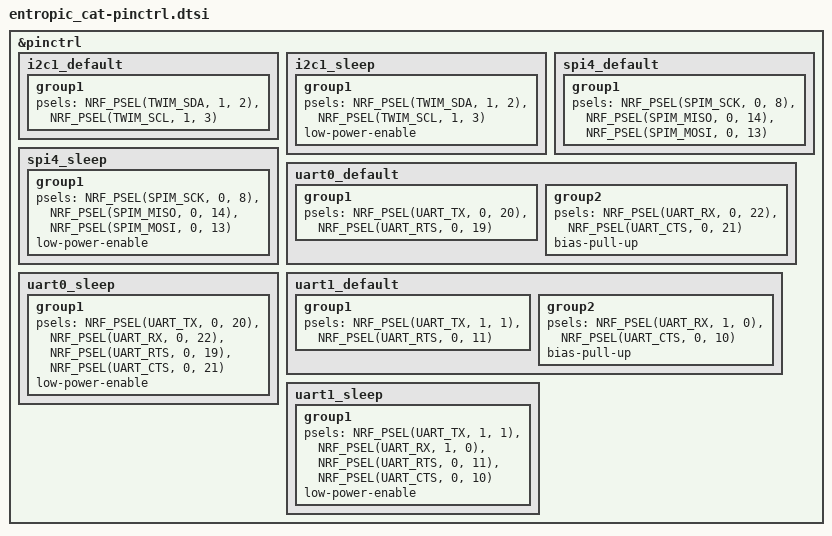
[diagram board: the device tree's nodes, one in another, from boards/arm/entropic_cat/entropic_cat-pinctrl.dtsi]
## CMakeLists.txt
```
cmake_minimum_required(VERSION 3.20.0)
find_package(Zephyr REQUIRED HINTS $ENV{ZEPHYR_BASE})

project(cat)

add_subdirectory(vendor)

target_sources(app PRIVATE src/main.c
    src/sen5x.c
    src/sunrise.c
    src/lps22hh.c)
```

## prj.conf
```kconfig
CONFIG_I2C=y

CONFIG_LOG=y
CONFIG_LOG_INFO_COLOR_GREEN=y
CONFIG_LOG_BACKEND_SHOW_COLOR=y

# Enable floats in printf calls
CONFIG_CBPRINTF_FP_SUPPORT=y

# Disable TF-M Secure UART, its addr space overlaps
# peripherals we use which causes a Bus Fault if enabled.
# See: https://academy.nordicsemi.com/courses/nrf-connect-sdk-intermediate/lessons/lesson-5-serial-peripheral-interface-spi/topic/exercise-1-10/
CONFIG_TFM_SECURE_UART=n
CONFIG_TFM_LOG_LEVEL_SILENCE=y
```

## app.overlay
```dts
&arduino_i2c {
	status = "okay";
	clock-frequency = <I2C_BITRATE_STANDARD>;
};
```

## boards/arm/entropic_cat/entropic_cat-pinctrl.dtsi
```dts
&pinctrl {
	i2c1_default: i2c1_default {
		group1 {
			psels = <NRF_PSEL(TWIM_SDA, 1, 2)>,
				<NRF_PSEL(TWIM_SCL, 1, 3)>;
		};
	};

	i2c1_sleep: i2c1_sleep {
		group1 {
			psels = <NRF_PSEL(TWIM_SDA, 1, 2)>,
				<NRF_PSEL(TWIM_SCL, 1, 3)>;
			low-power-enable;
		};
	};

	spi4_default: spi4_default {
		group1 {
			psels = <NRF_PSEL(SPIM_SCK, 0, 8)>,
				<NRF_PSEL(SPIM_MISO, 0, 14)>,
				<NRF_PSEL(SPIM_MOSI, 0, 13)>;
		};
	};

	spi4_sleep: spi4_sleep {
		group1 {
			psels = <NRF_PSEL(SPIM_SCK, 0, 8)>,
				<NRF_PSEL(SPIM_MISO, 0, 14)>,
				<NRF_PSEL(SPIM_MOSI, 0, 13)>;
			low-power-enable;
		};
	};

    /* The following are defaults from nrf5340-dk, TO BE UPDATED! */

	uart0_default: uart0_default {
		group1 {
			psels = <NRF_PSEL(UART_TX, 0, 20)>,
				<NRF_PSEL(UART_RTS, 0, 19)>;
		};
		group2 {
			psels = <NRF_PSEL(UART_RX, 0, 22)>,
				<NRF_PSEL(UART_CTS, 0, 21)>;
			bias-pull-up;
		};
	};

	uart0_sleep: uart0_sleep {
		group1 {
			psels = <NRF_PSEL(UART_TX, 0, 20)>,
				<NRF_PSEL(UART_RX, 0, 22)>,
				<NRF_PSEL(UART_RTS, 0, 19)>,
				<NRF_PSEL(UART_CTS, 0, 21)>;
			low-power-enable;
		};
	};

	uart1_default: uart1_default {
		group1 {
			psels = <NRF_PSEL(UART_TX, 1, 1)>,
				<NRF_PSEL(UART_RTS, 0, 11)>;
		};
		group2 {
			psels = <NRF_PSEL(UART_RX, 1, 0)>,
				<NRF_PSEL(UART_CTS, 0, 10)>;
			bias-pull-up;
		};
	};

	uart1_sleep: uart1_sleep {
		group1 {
			psels = <NRF_PSEL(UART_TX, 1, 1)>,
				<NRF_PSEL(UART_RX, 1, 0)>,
				<NRF_PSEL(UART_RTS, 0, 11)>,
				<NRF_PSEL(UART_CTS, 0, 10)>;
			low-power-enable;
		};
	};
};
```

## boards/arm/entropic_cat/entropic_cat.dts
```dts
// Copyright (c) 2024 Nordic Semiconductor ASA
// SPDX-License-Identifier: Apache-2.0

/dts-v1/;
#include <nordic/nrf5340_cpuappns_qkaa.dtsi>

/ {
	model = "entropic_cat";
	compatible = "entropic-engineering,entropic-cat";

	chosen {
		zephyr,sram = &sram0;
		zephyr,flash = &flash0;
		zephyr,code-partition = &slot0_ns_partition;
	};

	rgb_leds: ws2812 {
		compatible = "worldsemi,ws2812-gpio";
		chain-length = <8>;
		color-mapping = <LED_COLOR_ID_GREEN
		                 LED_COLOR_ID_RED
						 LED_COLOR_ID_BLUE>;
		gpios = <&gpio1 1 0>;
	};
};

&flash0 {
	partitions {
		compatible = "fixed-partitions";
		#address-cells = <1>;
		#size-cells = <1>;

		boot_partition: partition@0 {
			label = "mcuboot";
			reg = <0x0 0x10000>;
		};
		slot0_partition: partition@10000 {
			label = "image-0";
			reg = <0x10000 0x40000>;
		};
		slot0_ns_partition: partition@50000 {
			label = "image-0-nonsecure";
			reg = <0x50000 0x30000>;
		};
		slot1_partition: partition@80000 {
			label = "image-1";
			reg = <0x80000 0x40000>;
		};
		slot1_ns_partition: partition@c0000 {
			label = "image-1-nonsecure";
			reg = <0xc0000 0x30000>;
		};
		scratch_partition: partition@f0000 {
			label = "image-scratch";
			reg = <0xf0000 0xa000>;
		};
		storage_partition: partition@fa000 {
			label = "storage";
			reg = <0xfa000 0x6000>;
		};
	};
};



/* Default shared SRAM planning when building for nRF5340.
* This file is included by both nRF5340 CPUAPP (Application MCU)
* and nRF5340 CPUNET (Network MCU).
* - 64 kB SRAM allocated as Shared memory (sram0_shared)
* - Region defined after the image SRAM of Application MCU
*/

/ {
    chosen {
        /* shared memory reserved for the inter-processor communication */
        zephyr,ipc_shm = &sram0_shared;
    };

    reserved-memory {
        #address-cells = <1>;
        #size-cells = <1>;
        ranges;

        sram0_shared: memory@20070000 {
            /* SRAM allocated to shared memory */
            reg = <0x20070000 0x10000>;
        };
    };
};
```

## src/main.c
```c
#include <zephyr/kernel.h>
#include <zephyr/drivers/i2c.h>

#include "sensor.h"

static const struct device* dev_i2c = DEVICE_DT_GET(DT_NODELABEL(arduino_i2c));

static const struct sensor_t* sensors[] = {
    &sensor_sen5x,
    &sensor_sunrise,
    &sensor_lps22hh,
};


void sensor_read_loop(void) {
    bool is_ready = false;
    printf("Reading sensors in a loop...\n");
    while (true) {
        ARRAY_FOR_EACH(sensors, i) {
            const struct sensor_t* const s = sensors[i];
            if (s->is_faulted()) {
                printf("[sensor:%s] Faulted, re-initializing all sensors\n", s->name);
                return;
            } else if (s->is_ready(&is_ready) != 0) {
                printf("[sensor:%s] Ready check failed\n", s->name);
            } else if (!is_ready) {
                /* not ready, take no action */
            } else if (s->read() != 0) {
                printf("[sensor:%s] Read failed\n", s->name);
            } else {
                printf("[sensor:%s] success!\n", s->name);
            }
        }
        k_msleep(5000);
    }
    printf("Sensor read loop exited.\n");
}


int main(void)
{
    printf("henlo, friendo!\n");

    while (!device_is_ready(dev_i2c)) {
        printf("waiting for i2c to be ready...\n");
        k_msleep(100);
    }

    printf("i2c bus scan:\n");
    printf("    0  1  2  3  4  5  6  7  8  9  a  b  c  d  e  f\n");
    for (uint8_t y = 0; y <= 7; y++) {
        printf("%02x", y<<4);
        for (uint8_t x = 0; x <= 0xf; x++) {
            uint8_t addr = (y<<4) | x;
            uint8_t buf = 0;
            if (addr < 0x08 || addr > 0x77) {
                printf("   ");
            } else if (i2c_read(dev_i2c, &buf, 0, addr) == 0) {
                printf(" %02x", addr);
            } else {
                printf(" --");
            }
        }
        printf("\n");
    }

    while (true) {
        printf("Initializing sensors...\n");
        ARRAY_FOR_EACH(sensors, i) {
            const struct sensor_t* const s = sensors[i];
            if (s->init() != 0) {
                printf("[sensor:%s] Init failed :<\n", s->name);
            }
        }
        sensor_read_loop();
    }

    return 0;
}

//eof
```

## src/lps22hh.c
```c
#include <zephyr/drivers/i2c.h>
#include <zephyr/logging/log.h>

#include "lps22hh.h"

#include "sensor.h"

LOG_MODULE_REGISTER(lps22hh);

static const struct device* dev_i2c = DEVICE_DT_GET(DT_NODELABEL(arduino_i2c));

static int32_t io_init() { return 0; }
static int32_t io_deinit() { return 0; }
static int32_t io_get_tick() {
    LOG_ERR("%s not implemented", __PRETTY_FUNCTION__);
    k_panic();
    return 0;
}
static void io_delay(uint32_t) {
    LOG_ERR("%s not implemented", __PRETTY_FUNCTION__);
    k_panic();
}
static int32_t io_write_reg(uint16_t addr, uint16_t reg, uint8_t* data, uint16_t data_len) {
    return i2c_burst_write(dev_i2c, addr, (uint8_t)reg, data, data_len);
}
static int32_t io_read_reg(uint16_t addr, uint16_t reg, uint8_t* buf, uint16_t buf_len) {
    return i2c_burst_read(dev_i2c, addr, (uint8_t)reg, buf, buf_len);
}

static LPS22HH_Object_t obj = {0,};
static LPS22HH_IO_t io = {
    .Init = io_init,
    .DeInit = io_deinit,
    .BusType = LPS22HH_I2C_BUS,
    .Address = 0x5d,
    .WriteReg = io_write_reg,
    .ReadReg = io_read_reg,
    .GetTick = io_get_tick,
    .Delay = io_delay,
};

struct lps22hh_state_t {
    bool is_faulted;
};
static struct lps22hh_state_t state = {0,};

#define CHK(_ACT) do { \
    const int result = _ACT; \
    if (result != 0) { \
        LOG_ERR("Action %s failed with %d (%s)\n", #_ACT, result, strerror(result)); \
        state.is_faulted = true; \
        return result; \
    } \
} while(0)

int lps22hh_init()
{
    CHK(LPS22HH_RegisterBusIO(&obj, &io));
    CHK(LPS22HH_Init(&obj));
    CHK(LPS22HH_TEMP_Enable(&obj));
    CHK(LPS22HH_PRESS_Enable(&obj));
    state.is_faulted = false;
    return 0;
}

int lps22hh_is_ready(bool* is_ready)
{
    lps22hh_status_t status;
    CHK(lps22hh_status_reg_get(&(obj.Ctx), &status));
    *is_ready = status.t_da || status.p_da;
    return 0;
}

int lps22hh_read()
{
    float temp, pressure;
    CHK(LPS22HH_TEMP_GetTemperature(&obj, &temp));
    CHK(LPS22HH_PRESS_GetPressure(&obj, &pressure));
    LOG_INF("temp=%.2f  pressure=%.2f", temp, pressure);
    sunrise_update_pressure(pressure);
    return 0;
}

bool lps22hh_is_faulted()
{
    return state.is_faulted;
}

SENSOR_DEFINE(lps22hh);

//eof
```

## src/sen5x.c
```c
#include <zephyr/drivers/i2c.h>
#include <zephyr/logging/log.h>

#include "sensirion_i2c_hal.h"
#include "sen5x_i2c.h"

#include "sensor.h"

LOG_MODULE_REGISTER(sen5x);

static const struct device* dev_i2c = DEVICE_DT_GET(DT_NODELABEL(arduino_i2c));

struct sen5x_state_t {
    char name[32];
    char serial[32];
    uint8_t fw_maj, fw_min, hw_maj, hw_min, proto_maj, proto_min;
    bool fw_debug;

    double mc_pm1p0, mc_pm2p5, mc_pm4p0, mc_pm10p0;
    double humidity, temp_c;
    double voc_index, nox_index;
    uint32_t status;
    bool is_faulted;
};

static struct sen5x_state_t state = {0,};

#define CHK(_ACT) do { \
    const int result = _ACT; \
    if (result != 0) { \
        LOG_ERR("Action %s failed with %d (%s)\n", #_ACT, result, strerror(result)); \
        state.is_faulted = true; \
        return result; \
    } \
} while(0)

int sen5x_init()
{
    sensirion_i2c_hal_init(dev_i2c);
    CHK(sen5x_device_reset());
    CHK(sen5x_get_product_name(state.name, sizeof(state.name)));
    LOG_INF("name=%s", state.name);
    CHK(sen5x_get_serial_number(state.serial, sizeof(state.serial)));
    LOG_INF("serial=%s", state.serial);
    CHK(sen5x_get_version(
        &state.fw_maj, &state.fw_min, &state.fw_debug,
        &state.hw_maj, &state.hw_min,
        &state.proto_maj, &state.proto_min));
    LOG_INF("Firmware v%d.%d (debug=%s)", state.fw_maj, state.fw_min, (state.fw_debug ? "y":"n"));
    LOG_INF("Hardware v%d.%d", state.hw_maj, state.hw_min);
    LOG_INF("Protocol v%d.%d", state.proto_maj, state.proto_min);
    CHK(sen5x_start_measurement());
    return 0;
}

int sen5x_is_ready(bool* is_ready)
{
    CHK(sen5x_read_data_ready(is_ready));
    return 0;
}

int sen5x_read()
{
    uint32_t status;
    uint16_t mc_pm1p0, mc_pm2p5, mc_pm4p0, mc_pm10p0;
    int16_t humidity, temp;
    int16_t voc_index, nox_index;

    CHK(sen5x_read_and_clear_device_status(&status));
    //TODO: parse the status!!
    LOG_INF("status=%08x", status);

    CHK(sen5x_read_measured_values(
        &mc_pm1p0, &mc_pm2p5, &mc_pm4p0, &mc_pm10p0,
        &humidity, &temp, &voc_index, &nox_index));
    if (mc_pm1p0  == 0xFFFF ||
        mc_pm2p5  == 0xFFFF ||
        mc_pm4p0  == 0xFFFF ||
        mc_pm10p0 == 0xFFFF ||
        humidity  == 0x7FFF ||
        temp      == 0x7FFF ||
        voc_index == 0x7FFF ||
        nox_index == 0x7FFF)
    {
        LOG_WRN("not ready yet");
        return -EBUSY;
    }

    state.status = status;
    state.mc_pm1p0 = mc_pm1p0 / 10.0;
    state.mc_pm2p5 = mc_pm2p5 / 10.0;
    state.mc_pm4p0 = mc_pm4p0 / 10.0;
    state.mc_pm10p0 = mc_pm10p0 / 10.0;
    state.humidity = humidity / 100.0;
    state.temp_c = temp / 200.0;
    state.voc_index = voc_index / 10.0;
    state.nox_index = nox_index / 10.0;

    LOG_INF("PM(ug/m3): 1.0=%.1f  2.5=%.1f  4.0=%.1f  10.0=%.1f",
        state.mc_pm1p0, state.mc_pm2p5, state.mc_pm4p0, state.mc_pm10p0);
    LOG_INF("humidity=%.2f %%RH", state.humidity);
    LOG_INF("temp=%.3f C", state.temp_c);
    LOG_INF("voc_index=%.1f", state.voc_index);
    LOG_INF("nox_index=%.1f", state.nox_index);

    return 0;
}

bool sen5x_is_faulted()
{
    return state.is_faulted;
}

SENSOR_DEFINE(sen5x);

//eof
```

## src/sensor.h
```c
#pragma once

#include <zephyr/kernel.h>

/* Sensor definition.
 * 
 * For simplicity, state is private to each driver and 
 * only one copy is kept. If we ever need to support more
 * than one instance of a given sensor, can extend this
 * to have a state pointer and some macros to simplify
 * statically creating instances or whatever.
 */
struct sensor_t {
    char const* const name;
    int (*init)();
    int (*is_ready)(bool*);
    int (*read)();
    bool (*is_faulted)();
};

#define SENSOR_DECL(NAME) \
    extern struct sensor_t sensor_##NAME

#define SENSOR_DEFINE(NAME) \
    struct sensor_t sensor_##NAME = { \
        .name = #NAME, \
        .init = NAME##_init, \
        .is_ready = NAME##_is_ready, \
        .read = NAME##_read, \
        .is_faulted = NAME##_is_faulted, \
    }

SENSOR_DECL(sen5x);
SENSOR_DECL(sunrise);
SENSOR_DECL(lps22hh);

/* Update pressure value (hPa) for the sunrise co2 sensor */
int sunrise_update_pressure(float pressure_hpa);

//eof
```

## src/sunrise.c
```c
#include <zephyr/drivers/i2c.h>
#include <zephyr/logging/log.h>
#include <zephyr/kernel.h>

#include "sensor.h"
#include <zephyr/sys/byteorder.h>

LOG_MODULE_REGISTER(sunrise);

/* Sensor goes to sleep after this many milliseconds of SDA inactivity.
 * After this, needs another wake-up.
 * Note the sensor also goes to sleep immediately after a completed read or write sequence. */
#define TIMEOUT_MS 15
/* EEPROM writes take 25ms */
#define EEPROM_UPDATE_DELAY_MS 25

//TODO: Should we wrap all i2c calls to track last activity
// time so we can run wakeup automatically in case another
// thread interrupts us for longer than 15ms mid operation?

static const struct device* dev_i2c = DEVICE_DT_GET(DT_NODELABEL(arduino_i2c));

/* Maximum number of retries for wake-up attempts */
static const size_t MAX_RETRIES = 5;
/* Senseair Sunrise I2C device address */
static const uint16_t ADDR = 0x68;

struct sunrise_state_t {
    uint8_t count;
    //todo: timestamp for device needing wake-up?
    //todo: timestamp for device reading ready?
    int16_t pressure_0p1_hpa;
    bool is_faulted;
};
static struct sunrise_state_t state = {0,};


#pragma pack(push, 1)
#if !CONFIG_LITTLE_ENDIAN
#error "These structures assume little endian for bit packing"
#endif

/* ErrorStatus register (00h-01h) */
struct error_status_t {
    //TODO: verify this bit and byte ordering is correct
    uint8_t fatal_error                    : 1;
    uint8_t i2c_error                      : 1;
    uint8_t algorithm_error                : 1;
    uint8_t calibration_error              : 1;
    uint8_t self_diag_error                : 1;
    uint8_t out_of_range                   : 1;
    uint8_t memory_error                   : 1;
    uint8_t no_measurement_completed       : 1;

    uint8_t low_internal_regulator_voltage : 1;
    uint8_t measurement_timeout            : 1;
    uint8_t abnormal_signal_level          : 1;
    uint8_t reserved                       : 4;
    uint8_t scale_factor_error             : 1;
};
NRF_STATIC_ASSERT(sizeof(struct error_status_t) == 2, "error_status_t size wrong");

struct fw_rev_t {
    uint8_t main;
    uint8_t sub;
};
NRF_STATIC_ASSERT(sizeof(struct fw_rev_t) == 2, "fw_rev_t size wrong");

struct product_code_t {
    /* Product code (null-terminated ASCII string) */
    char code[16];
};
NRF_STATIC_ASSERT(sizeof(struct product_code_t) == 16, "product_code_t size wrong");

struct calibration_status_t {
    uint8_t _reserved_0 : 1;
    uint8_t _reserved_1 : 1;
    uint8_t factory_calibration_restored : 1;
    uint8_t abc_calibration : 1;
    uint8_t target_calibration : 1;
    uint8_t background_calibration : 1;
    uint8_t zero_calibration : 1;
    uint8_t _reserved_7 : 1;
};
NRF_STATIC_ASSERT(sizeof(struct calibration_status_t) == 1, "calibration_status_t size wrong");

/* If ABC is enabled in single measurement mode and the sensor
 * is powered down between measurements, these registers must
 * be read from the sensor after each measurement and written
 * back to the sensor after each power on (enable) before a new
 * measurement is triggered. */
struct abc_parameters_t {
    /* Time passed since last ABC calibration (hours) */
    uint16_t time;
    /* Parameters */
    uint8_t par[4];
};
NRF_STATIC_ASSERT(sizeof(struct abc_parameters_t) == 6, "abc_parameters_t size wrong");

/* If IIR filter is enabled in single measurement mode and sensor
 * is powered down between measurements, these registers must
 * be read from the sensor after each measurement and written
 * back to the sensor after each power on (enable) before a new
 * measurement is triggered. */
struct filter_parameters_t {
    /* Parameters */
    uint16_t par[7];
};
NRF_STATIC_ASSERT(sizeof(struct filter_parameters_t) == 14, "filter_parameters_t size wrong");

struct meter_control_t {
    uint8_t nrdy_disable : 1;
    uint8_t abc_disabled  : 1;
    uint8_t static_iir_filter_dis : 1;
    uint8_t dynamic_iir_filter_dis : 1;
    uint8_t pressure_compensation_dis : 1;
    uint8_t nrdy_invert_disabled : 1;
    uint8_t reserved_6 : 1;
    uint8_t reserved_7 : 1;
};
NRF_STATIC_ASSERT(sizeof(struct meter_control_t) == 1, "meter_control_t size wrong");

#pragma pack(pop)


enum calibration_cmd_t {
    CAL_RestoreFactoryCalibration = 0x7c02,
    CAL_ForcedAbcCalibration = 0x7c03,
    CAL_TargetCalibration = 0x7c05,
    CAL_BackgroundCalibration = 0x7c06,
    CAL_ZeroCalibration = 0x7c07,
};

enum measurement_mode_t {
    MODE_Continuous = 0,
    MODE_Single = 1,
};

enum scr_t {
    RESTART_SENSOR = 0xFF,
};


static inline void msleep_for_sure(int32_t ms) {
    while (ms > 0) {
        ms = k_msleep(ms);
    }
}


#define REG_RO(REGADDR,NAME,CTYPE,XFRM) \
    static inline int Read_##NAME(CTYPE* out) { \
        int result = i2c_burst_read(dev_i2c, ADDR, REGADDR, (uint8_t*)out, sizeof(CTYPE)); \
        *out = XFRM(*out); \
        return result; \
    }
#define REG_RW(REGADDR,NAME,CTYPE,XFRM) \
    REG_RO(REGADDR,NAME,CTYPE,XFRM) \
    static inline int Write_##NAME(CTYPE value) { \
        value = XFRM(value); \
        int result = i2c_burst_write(dev_i2c, ADDR, REGADDR, (uint8_t*)&value, sizeof(value)); \
        return result; \
    }
#define REG_EE(REGADDR,NAME,CTYPE,XFRM) \
    REG_RO(REGADDR,NAME,CTYPE,XFRM) \
    static inline int Write_##NAME(CTYPE value) { \
        value = XFRM(value); \
        int result = i2c_burst_write(dev_i2c, ADDR, REGADDR, (uint8_t*)&value, sizeof(value)); \
        if (result == 0) { \
            msleep_for_sure(EEPROM_UPDATE_DELAY_MS); \
        } \
        return result; \
    }

REG_RO(0x00, ErrorStatus, struct error_status_t,)
/* Measured concentration (ppm). Filtered. Pressure compensated. */
REG_RO(0x06, MeasuredConcentration_Filtered_PressureCompensated, int16_t, sys_be16_to_cpu)
/* Device temperature (°C * 100)
 * Example: 2223 means 22.23°C */
REG_RO(0x08, Temperature, int16_t, sys_be16_to_cpu)
/* Counter incremented after each measurement, 0-255. Wraps. */
REG_RO(0x0d, MeasurementCount, uint8_t,)
/* Time in present measurement cycle, in 2 second increments.
 * 0 when new measurement cycle started.
 * Example: value of 3 means 6 seconds passed in current measurement cycle */
REG_RO(0x0e, MeasurementCycleTime, uint16_t, sys_be16_to_cpu)
/* Measured concentration (ppm). Unfiltered. Pressure compensated. */
REG_RO(0x10, MeasuredConcentration_Unfiltered_PressureCompensated, int16_t, sys_be16_to_cpu)
/* Measured concentration (ppm). Filtered. Not pressure compensated. */
REG_RO(0x12, MeasuredConcentration_Filtered, int16_t, sys_be16_to_cpu)
/* Measured concentration (ppm). Unfiltered. Not pressure compensated. */
REG_RO(0x14, MeasuredConcentration_Unfiltered, int16_t, sys_be16_to_cpu)
/* Measured concentration, scaled by (TODO) */
REG_RO(0x1a, ScaledMeasuredConcentration, int16_t, sys_be16_to_cpu)
/* Counts while sensor is powered up. Unit: hours */
REG_RO(0x2a, ElapsedTimeCounter, uint32_t, sys_be32_to_cpu)
REG_RO(0x2f, FirmwareType, uint8_t,)
REG_RO(0x38, FirmwareRevision, struct fw_rev_t,)
REG_RO(0x3a, SensorID, uint32_t, sys_be32_to_cpu)
REG_RO(0x70, ProductCode, struct product_code_t,)

REG_RW(0x81, CalibrationStatus, struct calibration_status_t,)
REG_RW(0x82, CalibrationCommand, enum calibration_cmd_t,)
REG_RW(0x84, CalibrationTarget, int16_t, sys_be16_to_cpu)
REG_RW(0x86, MeasuredConcentrationOverride, uint16_t, sys_be16_to_cpu)
REG_RW(0x88, AbcParameters, struct abc_parameters_t,)
REG_RW(0x93, StartSingleMeasurement, uint8_t,)

REG_EE(0x95, MeasurementMode, enum measurement_mode_t,)
/* Measurement period (seconds). Only used in continuous mode.
 * Sensor reset required after modifying. */
//TODO: Validate the value, range is 2-65534 inclusive
REG_EE(0x96, MeasurementPeriod, uint16_t, sys_be16_to_cpu)
/* Number of samples in one measurement (1-1024, inclusive).
 * Sensor reset required after modifying. */
REG_EE(0x98, NumberOfSamples, uint16_t, sys_be16_to_cpu)
/* Period for ABC cycle (hours) */
REG_EE(0x9a, AbcPeriod, uint16_t, sys_be16_to_cpu)

/* Write any number to clear the ErrorStatus register */
REG_RW(0x9d, ClearErrorStatus, uint8_t,)

/* Target value for background and ABC calibrations (ppm) */
REG_EE(0x9e, AbcTarget, uint16_t, sys_be16_to_cpu)
/* Parameter for static IIR filter (2-10 inclusive).
 * Higher value corresponds to harder filtration. */
REG_EE(0xa1, StaticIirFilterParameter, uint8_t,)

/* Write 0xFF to restart the sensor */
REG_RW(0xa3, SCR, enum scr_t,)

REG_EE(0xa5, MeterControl, struct meter_control_t,)
/* Sensor address (1-127 inclusive) - default is 104 (0x68).
 * Sensor reset required after modifying.
 * Sensor does not validate the I2C address, DO NOT SET RESERVED OR INVALID ADDRESSES */
REG_EE(0xa7, SensorAddress, uint8_t,)
/* Concentration scale factor (numerator).
 * If both numerator and denominator are set to 0xFFFF, scaling is disabled.
 * Sensor reset required after modifying both values. */
REG_EE(0xa8, ConcentrationScaleFactor_Numerator, uint16_t, sys_be16_to_cpu)
/* Concentration scale factor (denominator).
 * If both numerator and denominator are set to 0xFFFF, scaling is disabled.
 * Sensor reset required after modifying both values. */
REG_EE(0xaa, ConcentrationScaleFactor_Denominator, uint16_t, sys_be16_to_cpu)

REG_RW(0xac, ScaledCalibrationTarget, uint16_t, sys_be16_to_cpu)
REG_RW(0xae, ScaledMeasuredConcentrationOverride, uint16_t, sys_be16_to_cpu)

REG_EE(0xb0, ScaledAbcTarget, uint16_t, sys_be16_to_cpu)

REG_RW(0xc1, Mirror_CalibrationStatus, struct calibration_status_t,)
REG_RW(0xc3, Mirror_StartSingleMeasurement, uint8_t,)
REG_RW(0xc4, Mirror_AbcParameters, struct abc_parameters_t,)

REG_RW(0xce, FilterParameters, struct filter_parameters_t,)

/* Barometric air pressure (unit: 0.1 hPa)
 * Range 3,000 - 13,000 (300 - 1300 hPa)
 * 
 * Values outside pressure range will set "out of range" error flag
 * and pressure compensation will proceed with min or max allowed
 * pressure value. */
REG_RW(0xdc, BarometricAirPressure, int16_t, sys_be16_to_cpu)

/* If pressure compensation and ABC are both enabled when the sensor
 * is used in single measurement mode, and powered down between
 * measurements, this register must be read from the sensor after each
 * measurement and written back to the sensor after each power on (enable)
 * before a new measurement is triggered. */
REG_RW(0xde, AbcBarometricPressure, int16_t, sys_be16_to_cpu)

#undef REG_EE
#undef REG_RW
#undef REG_RO


static inline int _wakeup() {
    uint8_t buf = 0;
    struct i2c_msg msg = {
        .buf = &buf,
        .len = 0,
        .flags = I2C_MSG_WRITE | I2C_MSG_STOP,
    };

    int result = 0;
    for (size_t retries = 0; retries < MAX_RETRIES; retries++) {
        result = i2c_transfer(dev_i2c, &msg, 1, ADDR);
        if (result == 0) {
            break;
        } else {
            LOG_WRN("wake-up retry %zu/%zu failed", retries+1, MAX_RETRIES);
        }
    }
    return result;
}

#define CHK(_ACT) do { \
    const int result = _ACT; \
    if (result != 0) { \
        LOG_ERR("Action %s failed with %d (%s)\n", #_ACT, result, strerror(result)); \
        state.is_faulted = true; \
        return result; \
    } \
} while(0)

int sunrise_init()
{
    CHK(_wakeup());
    
    uint8_t fw_type;
    uint32_t sensor_id;
    uint32_t elapsed_time_hrs;
    struct fw_rev_t fw_rev;
    struct product_code_t product_code;
    struct error_status_t error_status;
    struct calibration_status_t calibration_status;
    struct meter_control_t meter_ctrl;
    enum measurement_mode_t measurement_mode;
    CHK(Read_FirmwareType(&fw_type));
    CHK(Read_SensorID(&sensor_id));
    CHK(Read_FirmwareRevision(&fw_rev));
    CHK(Read_ElapsedTimeCounter(&elapsed_time_hrs));
    CHK(Read_ProductCode(&product_code));
    CHK(Read_ErrorStatus(&error_status));
    CHK(Read_CalibrationStatus(&calibration_status));
    CHK(Read_MeterControl(&meter_ctrl));
    CHK(Read_MeasurementMode(&measurement_mode));

    //TODO: ensure product code contains a null terminator and only printable ascii,
    // else print the hexdump of it instead

    printf("FW Type: %u  Rev: %u.%u\n", fw_type, fw_rev.main, fw_rev.sub);
    printf("Sensor ID: %08x\n", sensor_id);
    printf("Product Code: %s\n", product_code.code);
    printf("Elapsed Time: %u hours\n", elapsed_time_hrs);
    printf("Measurement Mode: %02x\n", measurement_mode);

    printf("Error Status: %04x\n", *(uint16_t*)&error_status);
    printf("                     fatal_error: %d\n", error_status.fatal_error);
    printf("                       i2c_error: %d\n", error_status.i2c_error);
    printf("                 algorithm_error: %d\n", error_status.algorithm_error);
    printf("               calibration_error: %d\n", error_status.calibration_error);
    printf("                 self_diag_error: %d\n", error_status.self_diag_error);
    printf("                    out_of_range: %d\n", error_status.out_of_range);
    printf("                    memory_error: %d\n", error_status.memory_error);
    printf("        no_measurement_completed: %d\n", error_status.no_measurement_completed);
    printf("  low_internal_regulator_voltage: %d\n", error_status.low_internal_regulator_voltage);
    printf("             measurement_timeout: %d\n", error_status.measurement_timeout);
    printf("           abnormal_signal_level: %d\n", error_status.abnormal_signal_level);
    printf("                        reserved: %d\n", error_status.reserved);
    printf("              scale_factor_error: %d\n", error_status.scale_factor_error);

    printf("Calibration Status: %02x\n", *(uint8_t*)&calibration_status);
    printf("                   _reserved_0: %d\n", calibration_status._reserved_0);
    printf("                   _reserved_1: %d\n", calibration_status._reserved_1);
    printf("  factory_calibration_restored: %d\n", calibration_status.factory_calibration_restored);
    printf("               abc_calibration: %d\n", calibration_status.abc_calibration);
    printf("            target_calibration: %d\n", calibration_status.target_calibration);
    printf("        background_calibration: %d\n", calibration_status.background_calibration);
    printf("              zero_calibration: %d\n", calibration_status.zero_calibration);
    printf("                   _reserved_7: %d\n", calibration_status._reserved_7);

    printf("Meter Control: %02x\n", *(uint8_t*)&meter_ctrl);
    printf("               nrdy_disable: %d\n", meter_ctrl.nrdy_disable);
    printf("               abc_disabled: %d\n", meter_ctrl.abc_disabled);
    printf("      static_iir_filter_dis: %d\n", meter_ctrl.static_iir_filter_dis);
    printf("     dynamic_iir_filter_dis: %d\n", meter_ctrl.dynamic_iir_filter_dis);
    printf("  pressure_compensation_dis: %d\n", meter_ctrl.pressure_compensation_dis);
    printf("       nrdy_invert_disabled: %d\n", meter_ctrl.nrdy_invert_disabled);
    printf("                 reserved_6: %d\n", meter_ctrl.reserved_6);
    printf("                 reserved_7: %d\n", meter_ctrl.reserved_7);

    if (meter_ctrl.pressure_compensation_dis) {
        LOG_INF("Enabling pressure compensation");
        meter_ctrl.pressure_compensation_dis = 0;
        CHK(Write_MeterControl(meter_ctrl));
    }

    return 0;
}

int sunrise_is_ready(bool* is_ready)
{
    uint8_t count;
    *is_ready = false;
    CHK(Read_MeasurementCount(&count));
    if (state.count != count) {
        *is_ready = true;
        LOG_INF("count: %d -> %d", state.count, count);
        state.count = count;
    }
    return 0;
}

int sunrise_read()
{
    int16_t ppm_filtered;
    int16_t ppm_filtered_compensated;
    CHK(Read_MeasuredConcentration_Filtered(&ppm_filtered));
    CHK(Read_MeasuredConcentration_Filtered_PressureCompensated(&ppm_filtered_compensated));
    LOG_INF("co2: %d ppm (filtered)", ppm_filtered);
    LOG_INF("co2: %d ppm (filtered, pressure compensated)", ppm_filtered_compensated);
    return 0;
}

bool sunrise_is_faulted()
{
    return false;
}

int sunrise_update_pressure(const float pressure_hpa)
{
    const int16_t pressure_0p1_hpa = pressure_hpa * 10;
    if (state.pressure_0p1_hpa == pressure_0p1_hpa) {
        return 0;
    }
    CHK(Write_BarometricAirPressure(pressure_0p1_hpa));
    state.pressure_0p1_hpa = pressure_0p1_hpa;
    LOG_INF("pressure update: %d e-1 hPa", pressure_0p1_hpa);
    return 0;
}

SENSOR_DEFINE(sunrise);

//eof
```
